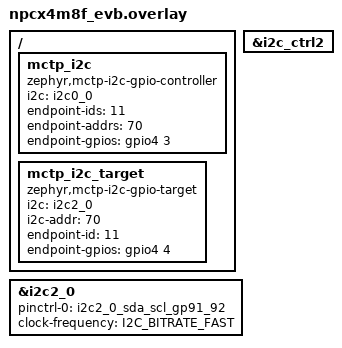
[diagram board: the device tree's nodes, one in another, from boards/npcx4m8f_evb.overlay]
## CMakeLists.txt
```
cmake_minimum_required(VERSION 3.28.0)

find_package(Zephyr REQUIRED HINTS $ENV{ZEPHYR_BASE})
project(mctp_i2c_gpio_test)

target_sources(app PRIVATE src/main.c)
```

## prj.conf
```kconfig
CONFIG_I2C=y
CONFIG_I2C_RTIO=y
CONFIG_I2C_TARGET=y
CONFIG_MCTP=y
CONFIG_MCTP_I2C_GPIO_CONTROLLER=y
CONFIG_MCTP_I2C_GPIO_TARGET=y
CONFIG_MCTP_HEAP_SIZE=12288
CONFIG_ZTEST=y

# Needs to be lower than that of CONFIG_RTIO_WORKQ_THREADS_POOL_PRIO (higher number means lower
# priority). libmctp calls callbacks from the RTIO workqueue. Making the test thread priority
# lower allows libmctp code to complete before the test thread destroys the libmctp context
# (preventing double frees).
CONFIG_ZTEST_THREAD_PRIORITY=1
```

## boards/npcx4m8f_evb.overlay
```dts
/*
 * Copyright (c) 2026 Intel Corporation
 *
 * SPDX-License-Identifier: Apache-2.0
 */

/* Connect both I2C and GPIOs:
 *  - I2C0_SCL to I2C2_SCL
 *  - I2C0_SDA to I2C2_SDA
 *  - GPIO44 to GPIO43
 * Note that there are different form factors of the board, so the actual pin
 * numbers may vary. Check the relevant schematics for details.
 */
&i2c_ctrl2 {
	status = "okay";
};

&i2c2_0 {
	pinctrl-0 = <&i2c2_0_sda_scl_gp91_92>;
	pinctrl-names = "default";
	clock-frequency = <I2C_BITRATE_FAST>;
	status = "okay";
};

/ {
	mctp_i2c: mctp_i2c {
		compatible = "zephyr,mctp-i2c-gpio-controller";
		i2c = <&i2c0_0>;
		endpoint-ids = <11>;
		endpoint-addrs = <70>;
		endpoint-gpios = <&gpio4 3 GPIO_ACTIVE_HIGH>;
	};

	mctp_i2c_target: mctp_i2c_target {
		compatible = "zephyr,mctp-i2c-gpio-target";
		i2c = <&i2c2_0>;
		i2c-addr = <70>;
		endpoint-id = <11>;
		endpoint-gpios = <&gpio4 4 GPIO_ACTIVE_HIGH>;
	};
};
```

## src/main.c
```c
/*
 * Copyright (c) 2025 Intel Corporation
 *
 * SPDX-License-Identifier: Apache-2.0
 */

#include <zephyr/types.h>
#include <zephyr/kernel.h>
#include <libmctp.h>
#include <zephyr/pmci/mctp/mctp_i2c_gpio_controller.h>
#include <zephyr/pmci/mctp/mctp_i2c_gpio_target.h>

#include <zephyr/ztest.h>

#define LOCAL_EID 20

MCTP_I2C_GPIO_CONTROLLER_DT_DEFINE(mctp_i2c_ctrl, DT_NODELABEL(mctp_i2c));
MCTP_I2C_GPIO_TARGET_DT_DEFINE(mctp_i2c_target, DT_NODELABEL(mctp_i2c_target));

K_SEM_DEFINE(mctp_rx, 0, 1);

struct reply_data {
	struct k_work work;
	struct mctp *mctp_ctx;
	uint8_t eid;
	const void *reply_msg;
	size_t reply_len;
};

bool ping_pong_done;

static struct reply_data reply_handler;

static const char big_message[] =
	"0123456789012345678901234567890123456789012345678901234567890123456789012345678 "
	"0123456789012345678901234567890123456789012345678901234567890123456789012345678 "
	"0123456789012345678901234567890123456789012345678901234567890123456789012345678 "
	"0123456789012345678901234567890123456789012345678901234567890123456789012345678 "
	"0123456789012345678901234567890123456789012345678901234567890123456789012345678 "
	"0123456789012345678901234567890123456789012345678901234567890123456789012345678 "
	"0123456789012345678901234567890123456789012345678901234567890123456789012345678 "
	"0123456789012345678901234567890123456789012345678901234567890123456789012345678 "
	"0123456789012345678901234567890123456789012345678901234567890123456789012345678 "
	"0123456789012345678901234567890123456789012345678901234567890123456789012345END";

static void target_reply(struct k_work *item)
{
	struct reply_data *reply = CONTAINER_OF(item, struct reply_data, work);
	int rc;

	TC_PRINT("Target replying to endpoint %d\n", reply->eid);
	rc = mctp_message_tx(reply->mctp_ctx, reply->eid, false, 0, (void *)reply->reply_msg,
			     reply->reply_len);
	zassert_ok(rc, "Failed to send reply message");
}

static void rx_message_target(uint8_t eid, bool tag_owner, uint8_t msg_tag, void *data,
			      void *msg, size_t len)
{
	ARG_UNUSED(tag_owner);
	ARG_UNUSED(msg_tag);
	ARG_UNUSED(data);
	ARG_UNUSED(len);

	TC_PRINT("Target received message \"%s\" from endpoint %d, queuing reply\n",
		(char *)msg, eid);

	zassert_ok(memcmp(msg, "ping", sizeof("ping")));

	reply_handler.eid = eid;
	k_work_submit(&reply_handler.work);
}

static void rx_message_target_big_msg(uint8_t eid, bool tag_owner, uint8_t msg_tag, void *data,
				      void *msg, size_t len)
{
	ARG_UNUSED(tag_owner);
	ARG_UNUSED(msg_tag);
	ARG_UNUSED(data);
	ARG_UNUSED(len);

	TC_PRINT("Target received big message from endpoint %d, queuing reply\n", eid);

	zassert_equal(len, sizeof(big_message));
	zassert_ok(memcmp(msg, big_message, sizeof(big_message)));

	reply_handler.eid = eid;
	k_work_submit(&reply_handler.work);
}

static struct mctp *init_target(void (*rx_callback)(uint8_t eid, bool tag_owner, uint8_t msg_tag,
						    void *data, void *msg, size_t len))
{
	struct mctp *mctp_ctx;

	TC_PRINT("MCTP Endpoint EID:%d on %s\n", mctp_i2c_target.endpoint_id, CONFIG_BOARD_TARGET);
	mctp_ctx = mctp_init();

	zassert_not_null(mctp_ctx, "Failed to initialize MCTP target context");
	mctp_register_bus(mctp_ctx, &mctp_i2c_target.binding, mctp_i2c_target.endpoint_id);
	mctp_set_rx_all(mctp_ctx, rx_callback, NULL);

	reply_handler.mctp_ctx = mctp_ctx;
	k_work_init(&reply_handler.work, target_reply);

	return mctp_ctx;
}

static void rx_message(uint8_t eid, bool tag_owner, uint8_t msg_tag, void *data, void *msg,
		       size_t len)
{
	TC_PRINT("Received message \"%s\" from endpoint %d to %d, msg_tag %d, len %zu\n",
		(char *)msg, eid, LOCAL_EID, msg_tag, len);

	zassert_ok(memcmp(msg, "pong", sizeof("pong")));

	ping_pong_done = true;
	k_sem_give(&mctp_rx);
}

static void rx_message_big(uint8_t eid, bool tag_owner, uint8_t msg_tag, void *data, void *msg,
			   size_t len)
{
	ARG_UNUSED(tag_owner);
	ARG_UNUSED(msg_tag);
	ARG_UNUSED(data);

	TC_PRINT("Received big message from endpoint %d to %d, len %zu\n", eid, LOCAL_EID, len);

	zassert_equal(len, sizeof(big_message));
	zassert_ok(memcmp(msg, big_message, sizeof(big_message)));

	ping_pong_done = true;
	k_sem_give(&mctp_rx);
}

ZTEST(mctp_i2c_gpio_test_suite, test_mctp_i2c_gpio_ping_pong)
{
	int rc;
	struct mctp *mctp_ctx, *mctp_ctx_target;

	mctp_ctx_target = init_target(rx_message_target);
	reply_handler.reply_msg = "pong";
	reply_handler.reply_len = sizeof("pong");

	TC_PRINT("MCTP Host EID:%d on %s\n", LOCAL_EID, CONFIG_BOARD_TARGET);
	mctp_ctx = mctp_init();

	zassert_not_null(mctp_ctx, "Failed to initialize MCTP context");
	mctp_register_bus(mctp_ctx, &mctp_i2c_ctrl.binding, LOCAL_EID);
	mctp_set_rx_all(mctp_ctx, rx_message, NULL);

	TC_PRINT("Sending message \"ping\" to endpoint %u\n",
		mctp_i2c_ctrl.endpoint_ids[0]);

	rc = mctp_message_tx(mctp_ctx, mctp_i2c_ctrl.endpoint_ids[0], false, 0, "ping",
			     sizeof("ping"));
	zassert_ok(rc, "Failed to send message");

	/* Wait ping-pong to complete */
	k_sem_take(&mctp_rx, K_SECONDS(5));

	zassert_true(ping_pong_done, "Ping-pong message exchange failed");

	mctp_destroy(mctp_ctx);
	mctp_destroy(mctp_ctx_target);
}

ZTEST(mctp_i2c_gpio_test_suite, test_mctp_i2c_gpio_ping_pong_big_message)
{
	int rc;
	struct mctp *mctp_ctx, *mctp_ctx_target;

	mctp_ctx_target = init_target(rx_message_target_big_msg);
	reply_handler.reply_msg = big_message;
	reply_handler.reply_len = sizeof(big_message);

	TC_PRINT("MCTP Host EID:%d on %s\n", LOCAL_EID, CONFIG_BOARD_TARGET);
	mctp_ctx = mctp_init();

	zassert_not_null(mctp_ctx, "Failed to initialize MCTP context");
	mctp_register_bus(mctp_ctx, &mctp_i2c_ctrl.binding, LOCAL_EID);
	mctp_set_rx_all(mctp_ctx, rx_message_big, NULL);

	TC_PRINT("Sending big message to endpoint %u\n", mctp_i2c_ctrl.endpoint_ids[0]);

	rc = mctp_message_tx(mctp_ctx, mctp_i2c_ctrl.endpoint_ids[0], false, 0, (void *)big_message,
			     sizeof(big_message));
	zassert_ok(rc, "Failed to send message");

	/* Wait ping-pong to complete */
	k_sem_take(&mctp_rx, K_SECONDS(5));

	zassert_true(ping_pong_done, "Ping-pong message exchange failed");

	mctp_destroy(mctp_ctx);
	mctp_destroy(mctp_ctx_target);
}

static void cleanup(void *p)
{
	ARG_UNUSED(p);

	ping_pong_done = false;
	mctp_i2c_gpio_target_unregister(&mctp_i2c_target);
}

ZTEST_SUITE(mctp_i2c_gpio_test_suite, NULL, NULL, NULL, cleanup, NULL);
```
